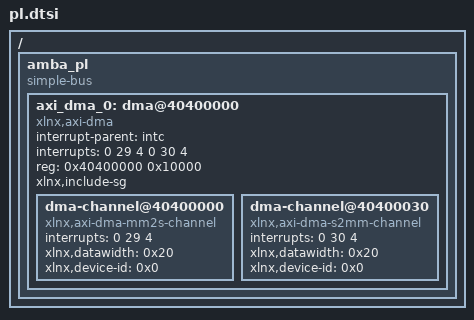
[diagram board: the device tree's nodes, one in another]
/*
 * CAUTION: This file is automatically generated by Xilinx.
 * Version:  
 * Today is: Wed Feb  4 23:00:29 2015
*/


/ {
	amba_pl: amba_pl {
		#address-cells = <1>;
		#size-cells = <1>;
		compatible = "simple-bus";
		ranges ;
		axi_dma_0: dma@40400000 {
			compatible = "xlnx,axi-dma";
			interrupt-parent = <&intc>;
			interrupts = <0 29 4 0 30 4>;
			reg = <0x40400000 0x10000>;
			xlnx,include-sg ;
			dma-channel@40400000 {
				compatible = "xlnx,axi-dma-mm2s-channel";
				interrupts = <0 29 4>;
				xlnx,datawidth = <0x20>;
				xlnx,device-id = <0x0>;
			};
			dma-channel@40400030 {
				compatible = "xlnx,axi-dma-s2mm-channel";
				interrupts = <0 30 4>;
				xlnx,datawidth = <0x20>;
				xlnx,device-id = <0x0>;
			};
		};
	};
};
